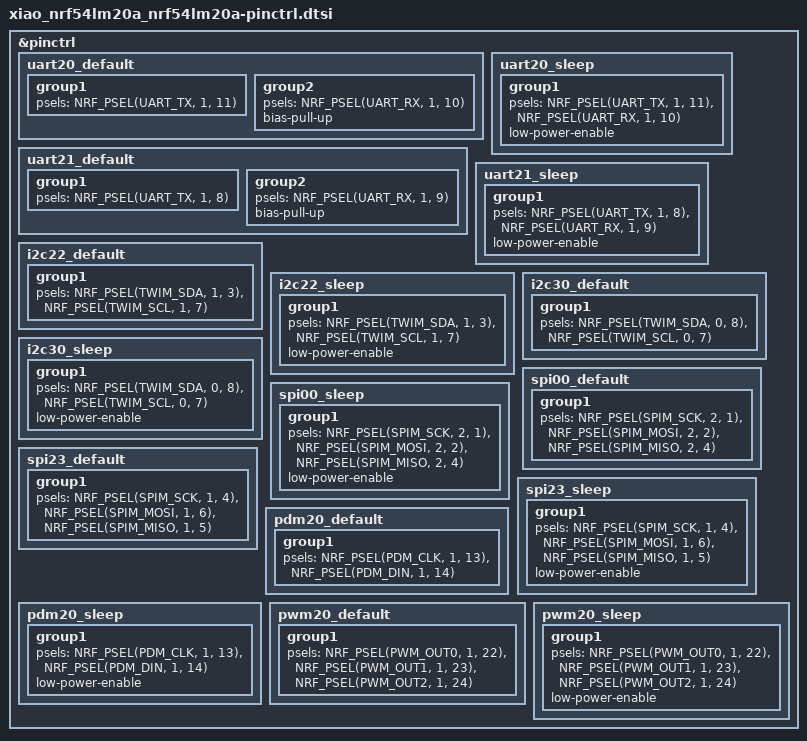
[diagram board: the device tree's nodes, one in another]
/*
 * Copyright (c) 2025 Seeed Technology Co., Ltd.
 * SPDX-License-Identifier: Apache-2.0
 */

&pinctrl {
	/omit-if-no-ref/ uart20_default: uart20_default {
		group1 {
			psels = <NRF_PSEL(UART_TX, 1, 11)>;
		};

		group2 {
			psels = <NRF_PSEL(UART_RX, 1, 10)>;
			bias-pull-up;
		};
	};

	/omit-if-no-ref/ uart20_sleep: uart20_sleep {
		group1 {
			psels = <NRF_PSEL(UART_TX, 1, 11)>,
				<NRF_PSEL(UART_RX, 1, 10)>;
			low-power-enable;
		};
	};

	/omit-if-no-ref/ uart21_default: uart21_default {
		group1 {
			psels = <NRF_PSEL(UART_TX, 1, 8)>;
		};

		group2 {
			psels = <NRF_PSEL(UART_RX, 1, 9)>;
			bias-pull-up;
		};
	};

	/omit-if-no-ref/ uart21_sleep: uart21_sleep {
		group1 {
			psels = <NRF_PSEL(UART_TX, 1, 8)>,
				<NRF_PSEL(UART_RX, 1, 9)>;
			low-power-enable;
		};
	};

	/omit-if-no-ref/ i2c22_default: i2c22_default {
		group1 {
			psels = <NRF_PSEL(TWIM_SDA, 1, 3)>,
				<NRF_PSEL(TWIM_SCL, 1, 7)>;
		};
	};

	/omit-if-no-ref/ i2c22_sleep: i2c22_sleep {
		group1 {
			psels = <NRF_PSEL(TWIM_SDA, 1, 3)>,
				<NRF_PSEL(TWIM_SCL, 1, 7)>;
			low-power-enable;
		};
	};

	/omit-if-no-ref/ i2c30_default: i2c30_default {
		group1 {
			psels = <NRF_PSEL(TWIM_SDA, 0, 8)>,
				<NRF_PSEL(TWIM_SCL, 0, 7)>;
		};
	};

	/omit-if-no-ref/ i2c30_sleep: i2c30_sleep {
		group1 {
			psels = <NRF_PSEL(TWIM_SDA, 0, 8)>,
				<NRF_PSEL(TWIM_SCL, 0, 7)>;
			low-power-enable;
		};
	};

	/omit-if-no-ref/ spi00_default: spi00_default {
		group1 {
			psels = <NRF_PSEL(SPIM_SCK, 2, 1)>,
				<NRF_PSEL(SPIM_MOSI, 2, 2)>,
				<NRF_PSEL(SPIM_MISO, 2, 4)>;
		};
	};

	/omit-if-no-ref/ spi00_sleep: spi00_sleep {
		group1 {
			psels = <NRF_PSEL(SPIM_SCK, 2, 1)>,
				<NRF_PSEL(SPIM_MOSI, 2, 2)>,
				<NRF_PSEL(SPIM_MISO, 2, 4)>;
			low-power-enable;
		};
	};

	/omit-if-no-ref/ spi23_default: spi23_default {
		group1 {
			psels = <NRF_PSEL(SPIM_SCK, 1, 4)>,
				<NRF_PSEL(SPIM_MOSI, 1, 6)>,
				<NRF_PSEL(SPIM_MISO, 1, 5)>;
		};
	};

	/omit-if-no-ref/ spi23_sleep: spi23_sleep {
		group1 {
			psels = <NRF_PSEL(SPIM_SCK, 1, 4)>,
				<NRF_PSEL(SPIM_MOSI, 1, 6)>,
				<NRF_PSEL(SPIM_MISO, 1, 5)>;
			low-power-enable;
		};
	};

	/omit-if-no-ref/ pdm20_default: pdm20_default {
		group1 {
			psels = <NRF_PSEL(PDM_CLK, 1, 13)>,
				<NRF_PSEL(PDM_DIN, 1, 14)>;
		};
	};

	/omit-if-no-ref/ pdm20_sleep: pdm20_sleep {
		group1 {
			psels = <NRF_PSEL(PDM_CLK, 1, 13)>,
				<NRF_PSEL(PDM_DIN, 1, 14)>;
			low-power-enable;
		};
	};

	/omit-if-no-ref/ pwm20_default: pwm20_default {
		group1 {
			psels = <NRF_PSEL(PWM_OUT0, 1, 22)>,
				<NRF_PSEL(PWM_OUT1, 1, 23)>,
				<NRF_PSEL(PWM_OUT2, 1, 24)>;
		};
	};

	/omit-if-no-ref/ pwm20_sleep: pwm20_sleep {
		group1 {
			psels = <NRF_PSEL(PWM_OUT0, 1, 22)>,
				<NRF_PSEL(PWM_OUT1, 1, 23)>,
				<NRF_PSEL(PWM_OUT2, 1, 24)>;
			low-power-enable;
		};
	};
};
